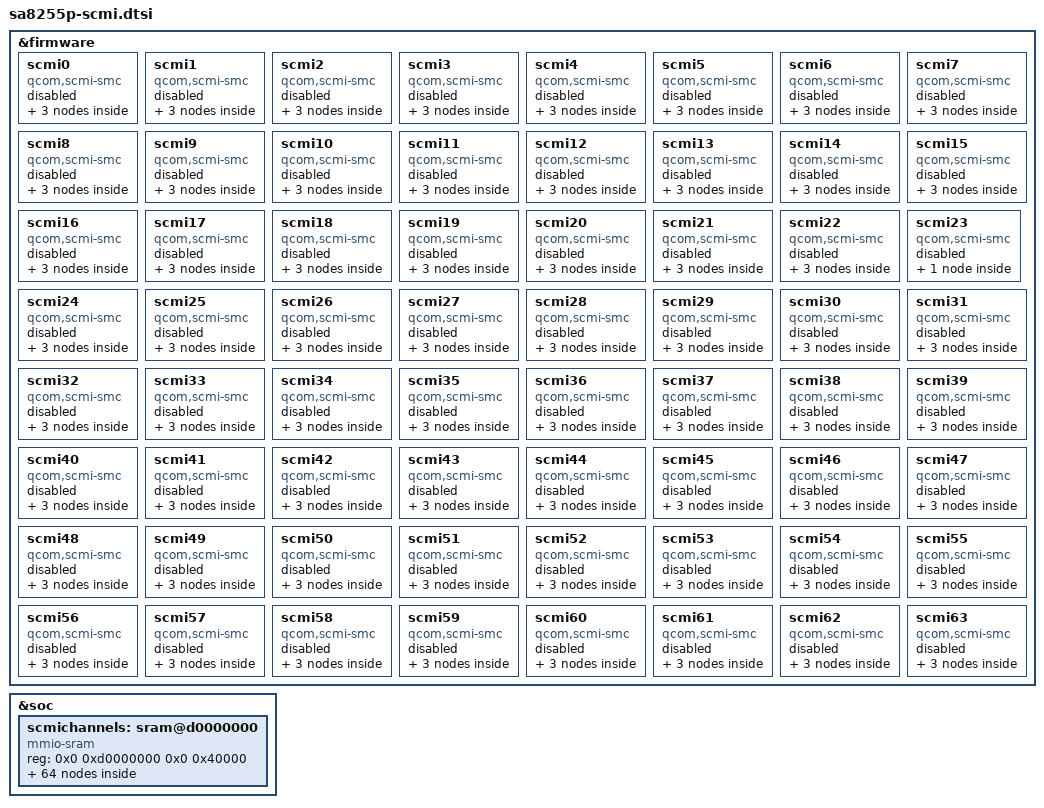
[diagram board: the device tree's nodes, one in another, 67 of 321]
// SPDX-License-Identifier: BSD-3-Clause
/*
 * Copyright (c) 2024 Qualcomm Innovation Center, Inc. All rights reserved.
 */

#include <dt-bindings/interrupt-controller/arm-gic.h>

&firmware {
	scmi0: scmi0 {
		compatible = "qcom,scmi-smc";
		arm,smc-id = <0xc6008012>;
		shmem = <&shmem0>;

		interrupts = <GIC_SPI 963 IRQ_TYPE_EDGE_RISING>;
		interrupt-names = "a2p";

		status = "disabled";

		#address-cells = <1>;
		#size-cells = <0>;

		scmi0_pd: protocol@11 {
			reg = <0x11>;
			#power-domain-cells = <1>;
		};

		scmi0_dvfs: protocol@13 {
			reg = <0x13>;
			#power-domain-cells = <1>;
		};

		scmi0_rst: protocol@16 {
			reg = <0x16>;
			#reset-cells = <1>;
		};
	};

	scmi1: scmi1 {
		compatible = "qcom,scmi-smc";
		arm,smc-id = <0xc6008012>;
		shmem = <&shmem1>;

		interrupts = <GIC_SPI 964 IRQ_TYPE_EDGE_RISING>;
		interrupt-names = "a2p";

		status = "disabled";

		#address-cells = <1>;
		#size-cells = <0>;

		scmi1_pd: protocol@11 {
			reg = <0x11>;
			#power-domain-cells = <1>;
		};

		scmi1_dvfs: protocol@13 {
			reg = <0x13>;
			#power-domain-cells = <1>;
		};

		scmi1_rst: protocol@16 {
			reg = <0x16>;
			#reset-cells = <1>;
		};
	};

	scmi2: scmi2 {
		compatible = "qcom,scmi-smc";
		arm,smc-id = <0xc6008012>;
		shmem = <&shmem2>;

		interrupts = <GIC_SPI 965 IRQ_TYPE_EDGE_RISING>;
		interrupt-names = "a2p";

		status = "disabled";

		#address-cells = <1>;
		#size-cells = <0>;

		scmi2_pd: protocol@11 {
			reg = <0x11>;
			#power-domain-cells = <1>;
		};

		scmi2_dvfs: protocol@13 {
			reg = <0x13>;
			#power-domain-cells = <1>;
		};

		scmi2_rst: protocol@16 {
			reg = <0x16>;
			#reset-cells = <1>;
		};
	};

	scmi3: scmi3 {
		compatible = "qcom,scmi-smc";
		arm,smc-id = <0xc6008012>;
		shmem = <&shmem3>;

		interrupts = <GIC_SPI 966 IRQ_TYPE_EDGE_RISING>;
		interrupt-names = "a2p";

		status = "disabled";

		#address-cells = <1>;
		#size-cells = <0>;

		scmi3_pd: protocol@11 {
			reg = <0x11>;
			#power-domain-cells = <1>;
		};

		scmi3_dvfs: protocol@13 {
			reg = <0x13>;
			#power-domain-cells = <1>;
		};

		scmi3_rst: protocol@16 {
			reg = <0x16>;
			#reset-cells = <1>;
		};
	};

	scmi4: scmi4 {
		compatible = "qcom,scmi-smc";
		arm,smc-id = <0xc6008012>;
		shmem = <&shmem4>;

		interrupts = <GIC_SPI 967 IRQ_TYPE_EDGE_RISING>;
		interrupt-names = "a2p";

		status = "disabled";

		#address-cells = <1>;
		#size-cells = <0>;

		scmi4_pd: protocol@11 {
			reg = <0x11>;
			#power-domain-cells = <1>;
		};

		scmi4_dvfs: protocol@13 {
			reg = <0x13>;
			#power-domain-cells = <1>;
		};

		scmi4_rst: protocol@16 {
			reg = <0x16>;
			#reset-cells = <1>;
		};
	};

	scmi5: scmi5 {
		compatible = "qcom,scmi-smc";
		arm,smc-id = <0xc6008012>;
		shmem = <&shmem5>;

		interrupts = <GIC_SPI 968 IRQ_TYPE_EDGE_RISING>;
		interrupt-names = "a2p";

		status = "disabled";

		#address-cells = <1>;
		#size-cells = <0>;

		scmi5_pd: protocol@11 {
			reg = <0x11>;
			#power-domain-cells = <1>;
		};

		scmi5_dvfs: protocol@13 {
			reg = <0x13>;
			#power-domain-cells = <1>;
		};

		scmi5_rst: protocol@16 {
			reg = <0x16>;
			#reset-cells = <1>;
		};
	};

	scmi6: scmi6 {
		compatible = "qcom,scmi-smc";
		arm,smc-id = <0xc6008012>;
		shmem = <&shmem6>;

		interrupts = <GIC_SPI 969 IRQ_TYPE_EDGE_RISING>;
		interrupt-names = "a2p";

		status = "disabled";

		#address-cells = <1>;
		#size-cells = <0>;

		scmi6_pd: protocol@11 {
			reg = <0x11>;
			#power-domain-cells = <1>;
		};

		scmi6_dvfs: protocol@13 {
			reg = <0x13>;
			#power-domain-cells = <1>;
		};

		scmi6_rst: protocol@16 {
			reg = <0x16>;
			#reset-cells = <1>;
		};
	};

	scmi7: scmi7 {
		compatible = "qcom,scmi-smc";
		arm,smc-id = <0xc6008012>;
		shmem = <&shmem7>;

		interrupts = <GIC_SPI 970 IRQ_TYPE_EDGE_RISING>;
		interrupt-names = "a2p";

		status = "disabled";

		#address-cells = <1>;
		#size-cells = <0>;

		scmi7_pd: protocol@11 {
			reg = <0x11>;
			#power-domain-cells = <1>;
		};

		scmi7_dvfs: protocol@13 {
			reg = <0x13>;
			#power-domain-cells = <1>;
		};

		scmi7_rst: protocol@16 {
			reg = <0x16>;
			#reset-cells = <1>;
		};
	};

	scmi8: scmi8 {
		compatible = "qcom,scmi-smc";
		arm,smc-id = <0xc6008012>;
		shmem = <&shmem8>;

		interrupts = <GIC_SPI 971 IRQ_TYPE_EDGE_RISING>;
		interrupt-names = "a2p";

		status = "disabled";

		#address-cells = <1>;
		#size-cells = <0>;

		scmi8_pd: protocol@11 {
			reg = <0x11>;
			#power-domain-cells = <1>;
		};

		scmi8_dvfs: protocol@13 {
			reg = <0x13>;
			#power-domain-cells = <1>;
		};

		scmi8_rst: protocol@16 {
			reg = <0x16>;
			#reset-cells = <1>;
		};
	};

	scmi9: scmi9 {
		compatible = "qcom,scmi-smc";
		arm,smc-id = <0xc6008012>;
		shmem = <&shmem9>;

		interrupts = <GIC_SPI 972 IRQ_TYPE_EDGE_RISING>;
		interrupt-names = "a2p";

		status = "disabled";

		#address-cells = <1>;
		#size-cells = <0>;

		scmi9_pd: protocol@11 {
			reg = <0x11>;
			#power-domain-cells = <1>;
		};

		scmi9_dvfs: protocol@13 {
			reg = <0x13>;
			#power-domain-cells = <1>;
		};

		scmi9_rst: protocol@16 {
			reg = <0x16>;
			#reset-cells = <1>;
		};
	};

	scmi10: scmi10 {
		compatible = "qcom,scmi-smc";
		arm,smc-id = <0xc6008012>;
		shmem = <&shmem10>;

		interrupts = <GIC_SPI 973 IRQ_TYPE_EDGE_RISING>;
		interrupt-names = "a2p";

		status = "disabled";

		#address-cells = <1>;
		#size-cells = <0>;

		scmi10_pd: protocol@11 {
			reg = <0x11>;
			#power-domain-cells = <1>;
		};

		scmi10_dvfs: protocol@13 {
			reg = <0x13>;
			#power-domain-cells = <1>;
		};

		scmi10_rst: protocol@16 {
			reg = <0x16>;
			#reset-cells = <1>;
		};
	};

	scmi11: scmi11 {
		compatible = "qcom,scmi-smc";
		arm,smc-id = <0xc6008012>;
		shmem = <&shmem11>;

		interrupts = <GIC_SPI 974 IRQ_TYPE_EDGE_RISING>;
		interrupt-names = "a2p";

		status = "disabled";

		#address-cells = <1>;
		#size-cells = <0>;

		scmi11_pd: protocol@11 {
			reg = <0x11>;
			#power-domain-cells = <1>;
		};

		scmi11_dvfs: protocol@13 {
			reg = <0x13>;
			#power-domain-cells = <1>;
		};

		scmi11_rst: protocol@16 {
			reg = <0x16>;
			#reset-cells = <1>;
		};
	};

	scmi12: scmi12 {
		compatible = "qcom,scmi-smc";
		arm,smc-id = <0xc6008012>;
		shmem = <&shmem12>;

		interrupts = <GIC_SPI 975 IRQ_TYPE_EDGE_RISING>;
		interrupt-names = "a2p";

		status = "disabled";

		#address-cells = <1>;
		#size-cells = <0>;

		scmi12_pd: protocol@11 {
			reg = <0x11>;
			#power-domain-cells = <1>;
		};

		scmi12_dvfs: protocol@13 {
			reg = <0x13>;
			#power-domain-cells = <1>;
		};

		scmi12_rst: protocol@16 {
			reg = <0x16>;
			#reset-cells = <1>;
		};
	};

	scmi13: scmi13 {
		compatible = "qcom,scmi-smc";
		arm,smc-id = <0xc6008012>;
		shmem = <&shmem13>;

		interrupts = <GIC_SPI 976 IRQ_TYPE_EDGE_RISING>;
		interrupt-names = "a2p";

		status = "disabled";

		#address-cells = <1>;
		#size-cells = <0>;

		scmi13_pd: protocol@11 {
			reg = <0x11>;
			#power-domain-cells = <1>;
		};

		scmi13_dvfs: protocol@13 {
			reg = <0x13>;
			#power-domain-cells = <1>;
		};

		scmi13_rst: protocol@16 {
			reg = <0x16>;
			#reset-cells = <1>;
		};
	};

	scmi14: scmi14 {
		compatible = "qcom,scmi-smc";
		arm,smc-id = <0xc6008012>;
		shmem = <&shmem14>;

		interrupts = <GIC_SPI 977 IRQ_TYPE_EDGE_RISING>;
		interrupt-names = "a2p";

		status = "disabled";

		#address-cells = <1>;
		#size-cells = <0>;

		scmi14_pd: protocol@11 {
			reg = <0x11>;
			#power-domain-cells = <1>;
		};

		scmi14_dvfs: protocol@13 {
			reg = <0x13>;
			#power-domain-cells = <1>;
		};

		scmi14_rst: protocol@16 {
			reg = <0x16>;
			#reset-cells = <1>;
		};
	};

	scmi15: scmi15 {
		compatible = "qcom,scmi-smc";
		arm,smc-id = <0xc6008012>;
		shmem = <&shmem15>;

		interrupts = <GIC_SPI 978 IRQ_TYPE_EDGE_RISING>;
		interrupt-names = "a2p";

		status = "disabled";

		#address-cells = <1>;
		#size-cells = <0>;

		scmi15_pd: protocol@11 {
			reg = <0x11>;
			#power-domain-cells = <1>;
		};

		scmi15_dvfs: protocol@13 {
			reg = <0x13>;
			#power-domain-cells = <1>;
		};

		scmi15_rst: protocol@16 {
			reg = <0x16>;
			#reset-cells = <1>;
		};
	};

	scmi16: scmi16 {
		compatible = "qcom,scmi-smc";
		arm,smc-id = <0xc6008012>;
		shmem = <&shmem16>;

		interrupts = <GIC_SPI 979 IRQ_TYPE_EDGE_RISING>;
		interrupt-names = "a2p";

		status = "disabled";

		#address-cells = <1>;
		#size-cells = <0>;

		scmi16_pd: protocol@11 {
			reg = <0x11>;
			#power-domain-cells = <1>;
		};

		scmi16_dvfs: protocol@13 {
			reg = <0x13>;
			#power-domain-cells = <1>;
		};

		scmi16_rst: protocol@16 {
			reg = <0x16>;
			#reset-cells = <1>;
		};
	};

	scmi17: scmi17 {
		compatible = "qcom,scmi-smc";
		arm,smc-id = <0xc6008012>;
		shmem = <&shmem17>;

		interrupts = <GIC_SPI 980 IRQ_TYPE_EDGE_RISING>;
		interrupt-names = "a2p";

		status = "disabled";

		#address-cells = <1>;
		#size-cells = <0>;

		scmi17_pd: protocol@11 {
			reg = <0x11>;
			#power-domain-cells = <1>;
		};

		scmi17_dvfs: protocol@13 {
			reg = <0x13>;
			#power-domain-cells = <1>;
		};

		scmi17_rst: protocol@16 {
			reg = <0x16>;
			#reset-cells = <1>;
		};
	};

	scmi18: scmi18 {
		compatible = "qcom,scmi-smc";
		arm,smc-id = <0xc6008012>;
		shmem = <&shmem18>;

		interrupts = <GIC_SPI 981 IRQ_TYPE_EDGE_RISING>;
		interrupt-names = "a2p";

		status = "disabled";

		#address-cells = <1>;
		#size-cells = <0>;

		scmi18_pd: protocol@11 {
			reg = <0x11>;
			#power-domain-cells = <1>;
		};

		scmi18_dvfs: protocol@13 {
			reg = <0x13>;
			#power-domain-cells = <1>;
		};

		scmi18_rst: protocol@16 {
			reg = <0x16>;
			#reset-cells = <1>;
		};
	};

	scmi19: scmi19 {
		compatible = "qcom,scmi-smc";
		arm,smc-id = <0xc6008012>;
		shmem = <&shmem19>;

		interrupts = <GIC_SPI 982 IRQ_TYPE_EDGE_RISING>;
		interrupt-names = "a2p";

		status = "disabled";

		#address-cells = <1>;
		#size-cells = <0>;

		scmi19_pd: protocol@11 {
			reg = <0x11>;
			#power-domain-cells = <1>;
		};

		scmi19_dvfs: protocol@13 {
			reg = <0x13>;
			#power-domain-cells = <1>;
		};

		scmi19_rst: protocol@16 {
			reg = <0x16>;
			#reset-cells = <1>;
		};
	};

	scmi20: scmi20 {
		compatible = "qcom,scmi-smc";
		arm,smc-id = <0xc6008012>;
		shmem = <&shmem20>;

		interrupts = <GIC_SPI 983 IRQ_TYPE_EDGE_RISING>;
		interrupt-names = "a2p";

		status = "disabled";

		#address-cells = <1>;
		#size-cells = <0>;

		scmi20_pd: protocol@11 {
			reg = <0x11>;
			#power-domain-cells = <1>;
		};

		scmi20_dvfs: protocol@13 {
			reg = <0x13>;
			#power-domain-cells = <1>;
		};

		scmi20_rst: protocol@16 {
			reg = <0x16>;
			#reset-cells = <1>;
		};
	};

	scmi21: scmi21 {
		compatible = "qcom,scmi-smc";
		arm,smc-id = <0xc6008012>;
		shmem = <&shmem21>;

		interrupts = <GIC_SPI 984 IRQ_TYPE_EDGE_RISING>;
		interrupt-names = "a2p";

		status = "disabled";

		#address-cells = <1>;
		#size-cells = <0>;

		scmi21_pd: protocol@11 {
			reg = <0x11>;
			#power-domain-cells = <1>;
		};

		scmi21_dvfs: protocol@13 {
			reg = <0x13>;
			#power-domain-cells = <1>;
		};

		scmi21_rst: protocol@16 {
			reg = <0x16>;
			#reset-cells = <1>;
		};
	};

	scmi22: scmi22 {
		compatible = "qcom,scmi-smc";
		arm,smc-id = <0xc6008012>;
		shmem = <&shmem22>;

		interrupts = <GIC_SPI 985 IRQ_TYPE_EDGE_RISING>;
		interrupt-names = "a2p";

		status = "disabled";

		#address-cells = <1>;
		#size-cells = <0>;

		scmi22_pd: protocol@11 {
			reg = <0x11>;
			#power-domain-cells = <1>;
		};

		scmi22_dvfs: protocol@13 {
			reg = <0x13>;
			#power-domain-cells = <1>;
		};

		scmi22_rst: protocol@16 {
			reg = <0x16>;
			#reset-cells = <1>;
		};
	};

	scmi23: scmi23 {
		compatible = "qcom,scmi-smc";
		arm,smc-id = <0xc6008012>;
		shmem = <&shmem23>;

		interrupts = <GIC_SPI 986 IRQ_TYPE_EDGE_RISING>;
		interrupt-names = "a2p";

		status = "disabled";

		#address-cells = <1>;
		#size-cells = <0>;

		scmi23_sensor: protocol@15 {
			reg = <0x15>;
			#thermal-sensor-cells = <1>;
		};
	};

	scmi24: scmi24 {
		compatible = "qcom,scmi-smc";
		arm,smc-id = <0xc6008012>;
		shmem = <&shmem24>;

		interrupts = <GIC_SPI 987 IRQ_TYPE_EDGE_RISING>;
		interrupt-names = "a2p";

		status = "disabled";

		#address-cells = <1>;
		#size-cells = <0>;

		scmi24_pd: protocol@11 {
			reg = <0x11>;
			#power-domain-cells = <1>;
		};

		scmi24_dvfs: protocol@13 {
			reg = <0x13>;
			#power-domain-cells = <1>;
		};

		scmi24_rst: protocol@16 {
			reg = <0x16>;
			#reset-cells = <1>;
		};
	};

	scmi25: scmi25 {
		compatible = "qcom,scmi-smc";
		arm,smc-id = <0xc6008012>;
		shmem = <&shmem25>;

		interrupts = <GIC_ESPI 0 IRQ_TYPE_EDGE_RISING>;
		interrupt-names = "a2p";

		status = "disabled";

		#address-cells = <1>;
		#size-cells = <0>;

		scmi25_pd: protocol@11 {
			reg = <0x11>;
			#power-domain-cells = <1>;
		};

		scmi25_dvfs: protocol@13 {
			reg = <0x13>;
			#power-domain-cells = <1>;
		};

		scmi25_rst: protocol@16 {
			reg = <0x16>;
			#reset-cells = <1>;
		};
	};

	scmi26: scmi26 {
		compatible = "qcom,scmi-smc";
		arm,smc-id = <0xc6008012>;
		shmem = <&shmem26>;

		interrupts = <GIC_ESPI 1 IRQ_TYPE_EDGE_RISING>;
		interrupt-names = "a2p";

		status = "disabled";

		#address-cells = <1>;
		#size-cells = <0>;

		scmi26_pd: protocol@11 {
			reg = <0x11>;
			#power-domain-cells = <1>;
		};

		scmi26_dvfs: protocol@13 {
			reg = <0x13>;
			#power-domain-cells = <1>;
		};

		scmi26_rst: protocol@16 {
			reg = <0x16>;
			#reset-cells = <1>;
		};
	};

	scmi27: scmi27 {
		compatible = "qcom,scmi-smc";
		arm,smc-id = <0xc6008012>;
		shmem = <&shmem27>;

		interrupts = <GIC_ESPI 2 IRQ_TYPE_EDGE_RISING>;
		interrupt-names = "a2p";

		status = "disabled";

		#address-cells = <1>;
		#size-cells = <0>;

		scmi27_pd: protocol@11 {
			reg = <0x11>;
			#power-domain-cells = <1>;
		};

		scmi27_dvfs: protocol@13 {
			reg = <0x13>;
			#power-domain-cells = <1>;
		};

		scmi27_rst: protocol@16 {
			reg = <0x16>;
			#reset-cells = <1>;
		};
	};

	scmi28: scmi28 {
		compatible = "qcom,scmi-smc";
		arm,smc-id = <0xc6008012>;
		shmem = <&shmem28>;

		interrupts = <GIC_ESPI 3 IRQ_TYPE_EDGE_RISING>;
		interrupt-names = "a2p";

		status = "disabled";

		#address-cells = <1>;
		#size-cells = <0>;

		scmi28_pd: protocol@11 {
			reg = <0x11>;
			#power-domain-cells = <1>;
		};

		scmi28_dvfs: protocol@13 {
			reg = <0x13>;
			#power-domain-cells = <1>;
		};

		scmi28_rst: protocol@16 {
			reg = <0x16>;
			#reset-cells = <1>;
		};
	};

	scmi29: scmi29 {
		compatible = "qcom,scmi-smc";
		arm,smc-id = <0xc6008012>;
		shmem = <&shmem29>;

		interrupts = <GIC_ESPI 4 IRQ_TYPE_EDGE_RISING>;
		interrupt-names = "a2p";

		status = "disabled";

		#address-cells = <1>;
		#size-cells = <0>;

		scmi29_pd: protocol@11 {
			reg = <0x11>;
			#power-domain-cells = <1>;
		};

		scmi29_dvfs: protocol@13 {
			reg = <0x13>;
			#power-domain-cells = <1>;
		};

		scmi29_rst: protocol@16 {
			reg = <0x16>;
			#reset-cells = <1>;
		};
	};

	scmi30: scmi30 {
		compatible = "qcom,scmi-smc";
		arm,smc-id = <0xc6008012>;
		shmem = <&shmem30>;

		interrupts = <GIC_ESPI 5 IRQ_TYPE_EDGE_RISING>;
		interrupt-names = "a2p";

		status = "disabled";

		#address-cells = <1>;
		#size-cells = <0>;

		scmi30_pd: protocol@11 {
			reg = <0x11>;
			#power-domain-cells = <1>;
		};

		scmi30_dvfs: protocol@13 {
			reg = <0x13>;
			#power-domain-cells = <1>;
		};

		scmi30_rst: protocol@16 {
			reg = <0x16>;
			#reset-cells = <1>;
		};
	};

	scmi31: scmi31 {
		compatible = "qcom,scmi-smc";
		arm,smc-id = <0xc6008012>;
		shmem = <&shmem31>;

		interrupts = <GIC_ESPI 6 IRQ_TYPE_EDGE_RISING>;
		interrupt-names = "a2p";

		status = "disabled";

		#address-cells = <1>;
		#size-cells = <0>;

		scmi31_pd: protocol@11 {
			reg = <0x11>;
			#power-domain-cells = <1>;
		};

		scmi31_dvfs: protocol@13 {
			reg = <0x13>;
			#power-domain-cells = <1>;
		};

		scmi31_rst: protocol@16 {
			reg = <0x16>;
			#reset-cells = <1>;
		};
	};

	scmi32: scmi32 {
		compatible = "qcom,scmi-smc";
		arm,smc-id = <0xc6008012>;
		shmem = <&shmem32>;

		interrupts = <GIC_ESPI 7 IRQ_TYPE_EDGE_RISING>;
		interrupt-names = "a2p";

		status = "disabled";

		#address-cells = <1>;
		#size-cells = <0>;

		scmi32_pd: protocol@11 {
			reg = <0x11>;
			#power-domain-cells = <1>;
		};

		scmi32_dvfs: protocol@13 {
			reg = <0x13>;
			#power-domain-cells = <1>;
		};

		scmi32_rst: protocol@16 {
			reg = <0x16>;
			#reset-cells = <1>;
		};
	};

	scmi33: scmi33 {
		compatible = "qcom,scmi-smc";
		arm,smc-id = <0xc6008012>;
		shmem = <&shmem33>;

		interrupts = <GIC_ESPI 8 IRQ_TYPE_EDGE_RISING>;
		interrupt-names = "a2p";

		status = "disabled";

		#address-cells = <1>;
		#size-cells = <0>;

		scmi33_pd: protocol@11 {
			reg = <0x11>;
			#power-domain-cells = <1>;
		};

		scmi33_dvfs: protocol@13 {
			reg = <0x13>;
			#power-domain-cells = <1>;
		};

		scmi33_rst: protocol@16 {
			reg = <0x16>;
			#reset-cells = <1>;
		};
	};

	scmi34: scmi34 {
		compatible = "qcom,scmi-smc";
		arm,smc-id = <0xc6008012>;
		shmem = <&shmem34>;

		interrupts = <GIC_ESPI 9 IRQ_TYPE_EDGE_RISING>;
		interrupt-names = "a2p";

		status = "disabled";

		#address-cells = <1>;
		#size-cells = <0>;

		scmi34_pd: protocol@11 {
			reg = <0x11>;
			#power-domain-cells = <1>;
		};

		scmi34_dvfs: protocol@13 {
			reg = <0x13>;
			#power-domain-cells = <1>;
		};

		scmi34_rst: protocol@16 {
			reg = <0x16>;
			#reset-cells = <1>;
		};
	};

	scmi35: scmi35 {
		compatible = "qcom,scmi-smc";
		arm,smc-id = <0xc6008012>;
		shmem = <&shmem35>;

		interrupts = <GIC_ESPI 10 IRQ_TYPE_EDGE_RISING>;
		interrupt-names = "a2p";

		status = "disabled";

		#address-cells = <1>;
		#size-cells = <0>;

		scmi35_pd: protocol@11 {
			reg = <0x11>;
			#power-domain-cells = <1>;
		};

		scmi35_dvfs: protocol@13 {
			reg = <0x13>;
			#power-domain-cells = <1>;
		};

		scmi35_rst: protocol@16 {
			reg = <0x16>;
			#reset-cells = <1>;
		};
	};

	scmi36: scmi36 {
		compatible = "qcom,scmi-smc";
		arm,smc-id = <0xc6008012>;
		shmem = <&shmem36>;

		interrupts = <GIC_ESPI 11 IRQ_TYPE_EDGE_RISING>;
		interrupt-names = "a2p";

		status = "disabled";

		#address-cells = <1>;
		#size-cells = <0>;

		scmi36_pd: protocol@11 {
			reg = <0x11>;
			#power-domain-cells = <1>;
		};

		scmi36_dvfs: protocol@13 {
			reg = <0x13>;
			#power-domain-cells = <1>;
		};

		scmi36_rst: protocol@16 {
			reg = <0x16>;
			#reset-cells = <1>;
		};
	};

	scmi37: scmi37 {
		compatible = "qcom,scmi-smc";
		arm,smc-id = <0xc6008012>;
		shmem = <&shmem37>;

		interrupts = <GIC_ESPI 12 IRQ_TYPE_EDGE_RISING>;
		interrupt-names = "a2p";

		status = "disabled";

		#address-cells = <1>;
		#size-cells = <0>;

		scmi37_pd: protocol@11 {
			reg = <0x11>;
			#power-domain-cells = <1>;
		};

		scmi37_dvfs: protocol@13 {
			reg = <0x13>;
			#power-domain-cells = <1>;
		};

		scmi37_rst: protocol@16 {
			reg = <0x16>;
			#reset-cells = <1>;
		};
	};

	scmi38: scmi38 {
		compatible = "qcom,scmi-smc";
		arm,smc-id = <0xc6008012>;
		shmem = <&shmem38>;

		interrupts = <GIC_ESPI 13 IRQ_TYPE_EDGE_RISING>;
		interrupt-names = "a2p";

		status = "disabled";

		#address-cells = <1>;
		#size-cells = <0>;

		scmi38_pd: protocol@11 {
			reg = <0x11>;
			#power-domain-cells = <1>;
		};

		scmi38_dvfs: protocol@13 {
			reg = <0x13>;
			#power-domain-cells = <1>;
		};

		scmi38_rst: protocol@16 {
			reg = <0x16>;
			#reset-cells = <1>;
		};
	};

	scmi39: scmi39 {
		compatible = "qcom,scmi-smc";
		arm,smc-id = <0xc6008012>;
		shmem = <&shmem39>;

		interrupts = <GIC_ESPI 14 IRQ_TYPE_EDGE_RISING>;
		interrupt-names = "a2p";

		status = "disabled";

		#address-cells = <1>;
		#size-cells = <0>;

		scmi39_pd: protocol@11 {
			reg = <0x11>;
			#power-domain-cells = <1>;
		};

		scmi39_dvfs: protocol@13 {
			reg = <0x13>;
			#power-domain-cells = <1>;
		};

		scmi39_rst: protocol@16 {
			reg = <0x16>;
			#reset-cells = <1>;
		};
	};

	scmi40: scmi40 {
		compatible = "qcom,scmi-smc";
		arm,smc-id = <0xc6008012>;
		shmem = <&shmem40>;

		interrupts = <GIC_ESPI 15 IRQ_TYPE_EDGE_RISING>;
		interrupt-names = "a2p";

		status = "disabled";

		#address-cells = <1>;
		#size-cells = <0>;

		scmi40_pd: protocol@11 {
			reg = <0x11>;
			#power-domain-cells = <1>;
		};

		scmi40_dvfs: protocol@13 {
			reg = <0x13>;
			#power-domain-cells = <1>;
		};

		scmi40_rst: protocol@16 {
			reg = <0x16>;
			#reset-cells = <1>;
		};
	};

	scmi41: scmi41 {
		compatible = "qcom,scmi-smc";
		arm,smc-id = <0xc6008012>;
		shmem = <&shmem41>;

		interrupts = <GIC_ESPI 16 IRQ_TYPE_EDGE_RISING>;
		interrupt-names = "a2p";

		status = "disabled";

		#address-cells = <1>;
		#size-cells = <0>;

		scmi41_pd: protocol@11 {
			reg = <0x11>;
			#power-domain-cells = <1>;
		};

		scmi41_dvfs: protocol@13 {
			reg = <0x13>;
			#power-domain-cells = <1>;
		};

		scmi41_rst: protocol@16 {
			reg = <0x16>;
			#reset-cells = <1>;
		};
	};

	scmi42: scmi42 {
		compatible = "qcom,scmi-smc";
		arm,smc-id = <0xc6008012>;
		shmem = <&shmem42>;

		interrupts = <GIC_ESPI 17 IRQ_TYPE_EDGE_RISING>;
		interrupt-names = "a2p";

		status = "disabled";

		#address-cells = <1>;
		#size-cells = <0>;

		scmi42_pd: protocol@11 {
			reg = <0x11>;
			#power-domain-cells = <1>;
		};

		scmi42_dvfs: protocol@13 {
			reg = <0x13>;
			#power-domain-cells = <1>;
		};

		scmi42_rst: protocol@16 {
			reg = <0x16>;
			#reset-cells = <1>;
		};
	};

	scmi43: scmi43 {
		compatible = "qcom,scmi-smc";
		arm,smc-id = <0xc6008012>;
		shmem = <&shmem43>;

		interrupts = <GIC_ESPI 18 IRQ_TYPE_EDGE_RISING>;
		interrupt-names = "a2p";

		status = "disabled";

		#address-cells = <1>;
		#size-cells = <0>;

		scmi43_pd: protocol@11 {
			reg = <0x11>;
			#power-domain-cells = <1>;
		};

		scmi43_dvfs: protocol@13 {
			reg = <0x13>;
			#power-domain-cells = <1>;
		};

		scmi43_rst: protocol@16 {
			reg = <0x16>;
			#reset-cells = <1>;
		};
	};

	scmi44: scmi44 {
		compatible = "qcom,scmi-smc";
		arm,smc-id = <0xc6008012>;
		shmem = <&shmem44>;

		interrupts = <GIC_ESPI 19 IRQ_TYPE_EDGE_RISING>;
		interrupt-names = "a2p";

		status = "disabled";

		#address-cells = <1>;
		#size-cells = <0>;

		scmi44_pd: protocol@11 {
			reg = <0x11>;
			#power-domain-cells = <1>;
		};

		scmi44_dvfs: protocol@13 {
			reg = <0x13>;
			#power-domain-cells = <1>;
		};

		scmi44_rst: protocol@16 {
			reg = <0x16>;
			#reset-cells = <1>;
		};
	};

	scmi45: scmi45 {
		compatible = "qcom,scmi-smc";
		arm,smc-id = <0xc6008012>;
		shmem = <&shmem45>;

		interrupts = <GIC_ESPI 20 IRQ_TYPE_EDGE_RISING>;
		interrupt-names = "a2p";

		status = "disabled";

		#address-cells = <1>;
		#size-cells = <0>;

		scmi45_pd: protocol@11 {
			reg = <0x11>;
			#power-domain-cells = <1>;
		};

		scmi45_dvfs: protocol@13 {
			reg = <0x13>;
			#power-domain-cells = <1>;
		};

		scmi45_rst: protocol@16 {
			reg = <0x16>;
			#reset-cells = <1>;
		};
	};

	scmi46: scmi46 {
		compatible = "qcom,scmi-smc";
		arm,smc-id = <0xc6008012>;
		shmem = <&shmem46>;

		interrupts = <GIC_ESPI 21 IRQ_TYPE_EDGE_RISING>;
		interrupt-names = "a2p";

		status = "disabled";

		#address-cells = <1>;
		#size-cells = <0>;

		scmi46_pd: protocol@11 {
			reg = <0x11>;
			#power-domain-cells = <1>;
		};

		scmi46_dvfs: protocol@13 {
			reg = <0x13>;
			#power-domain-cells = <1>;
		};

		scmi46_rst: protocol@16 {
			reg = <0x16>;
			#reset-cells = <1>;
		};
	};

	scmi47: scmi47 {
		compatible = "qcom,scmi-smc";
		arm,smc-id = <0xc6008012>;
		shmem = <&shmem47>;

		interrupts = <GIC_ESPI 22 IRQ_TYPE_EDGE_RISING>;
		interrupt-names = "a2p";

		status = "disabled";

		#address-cells = <1>;
		#size-cells = <0>;

		scmi47_pd: protocol@11 {
			reg = <0x11>;
			#power-domain-cells = <1>;
		};

		scmi47_dvfs: protocol@13 {
			reg = <0x13>;
			#power-domain-cells = <1>;
		};

		scmi47_rst: protocol@16 {
			reg = <0x16>;
			#reset-cells = <1>;
		};
	};

	scmi48: scmi48 {
		compatible = "qcom,scmi-smc";
		arm,smc-id = <0xc6008012>;
		shmem = <&shmem48>;

		interrupts = <GIC_ESPI 23 IRQ_TYPE_EDGE_RISING>;
		interrupt-names = "a2p";

		status = "disabled";

		#address-cells = <1>;
		#size-cells = <0>;

		scmi48_pd: protocol@11 {
			reg = <0x11>;
			#power-domain-cells = <1>;
		};

		scmi48_dvfs: protocol@13 {
			reg = <0x13>;
			#power-domain-cells = <1>;
		};

		scmi48_rst: protocol@16 {
			reg = <0x16>;
			#reset-cells = <1>;
		};
	};

	scmi49: scmi49 {
		compatible = "qcom,scmi-smc";
		arm,smc-id = <0xc6008012>;
		shmem = <&shmem49>;

		interrupts = <GIC_ESPI 24 IRQ_TYPE_EDGE_RISING>;
		interrupt-names = "a2p";

		status = "disabled";

		#address-cells = <1>;
		#size-cells = <0>;

		scmi49_pd: protocol@11 {
			reg = <0x11>;
			#power-domain-cells = <1>;
		};

		scmi49_dvfs: protocol@13 {
			reg = <0x13>;
			#power-domain-cells = <1>;
		};

		scmi49_rst: protocol@16 {
			reg = <0x16>;
			#reset-cells = <1>;
		};
	};

	scmi50: scmi50 {
		compatible = "qcom,scmi-smc";
		arm,smc-id = <0xc6008012>;
		shmem = <&shmem50>;

		interrupts = <GIC_ESPI 25 IRQ_TYPE_EDGE_RISING>;
		interrupt-names = "a2p";

		status = "disabled";

		#address-cells = <1>;
		#size-cells = <0>;

		scmi50_pd: protocol@11 {
			reg = <0x11>;
			#power-domain-cells = <1>;
		};

		scmi50_dvfs: protocol@13 {
			reg = <0x13>;
			#power-domain-cells = <1>;
		};

		scmi50_rst: protocol@16 {
			reg = <0x16>;
			#reset-cells = <1>;
		};
	};

	scmi51: scmi51 {
		compatible = "qcom,scmi-smc";
		arm,smc-id = <0xc6008012>;
		shmem = <&shmem51>;

		interrupts = <GIC_ESPI 26 IRQ_TYPE_EDGE_RISING>;
		interrupt-names = "a2p";

		status = "disabled";

		#address-cells = <1>;
		#size-cells = <0>;

		scmi51_pd: protocol@11 {
			reg = <0x11>;
			#power-domain-cells = <1>;
		};

		scmi51_dvfs: protocol@13 {
			reg = <0x13>;
			#power-domain-cells = <1>;
		};

		scmi51_rst: protocol@16 {
			reg = <0x16>;
			#reset-cells = <1>;
		};
	};

	scmi52: scmi52 {
		compatible = "qcom,scmi-smc";
		arm,smc-id = <0xc6008012>;
		shmem = <&shmem52>;

		interrupts = <GIC_ESPI 27 IRQ_TYPE_EDGE_RISING>;
		interrupt-names = "a2p";

		status = "disabled";

		#address-cells = <1>;
		#size-cells = <0>;

		scmi52_pd: protocol@11 {
			reg = <0x11>;
			#power-domain-cells = <1>;
		};

		scmi52_dvfs: protocol@13 {
			reg = <0x13>;
			#power-domain-cells = <1>;
		};

		scmi52_rst: protocol@16 {
			reg = <0x16>;
			#reset-cells = <1>;
		};
	};

	scmi53: scmi53 {
		compatible = "qcom,scmi-smc";
		arm,smc-id = <0xc6008012>;
		shmem = <&shmem53>;

		interrupts = <GIC_ESPI 28 IRQ_TYPE_EDGE_RISING>;
		interrupt-names = "a2p";

		status = "disabled";

		#address-cells = <1>;
		#size-cells = <0>;

		scmi53_pd: protocol@11 {
			reg = <0x11>;
			#power-domain-cells = <1>;
		};

		scmi53_dvfs: protocol@13 {
			reg = <0x13>;
			#power-domain-cells = <1>;
		};

		scmi53_rst: protocol@16 {
			reg = <0x16>;
			#reset-cells = <1>;
		};
	};

	scmi54: scmi54 {
		compatible = "qcom,scmi-smc";
		arm,smc-id = <0xc6008012>;
		shmem = <&shmem54>;

		interrupts = <GIC_ESPI 29 IRQ_TYPE_EDGE_RISING>;
		interrupt-names = "a2p";

		status = "disabled";

		#address-cells = <1>;
		#size-cells = <0>;

		scmi54_pd: protocol@11 {
			reg = <0x11>;
			#power-domain-cells = <1>;
		};

		scmi54_dvfs: protocol@13 {
			reg = <0x13>;
			#power-domain-cells = <1>;
		};

		scmi54_rst: protocol@16 {
			reg = <0x16>;
			#reset-cells = <1>;
		};
	};

	scmi55: scmi55 {
		compatible = "qcom,scmi-smc";
		arm,smc-id = <0xc6008012>;
		shmem = <&shmem55>;

		interrupts = <GIC_ESPI 30 IRQ_TYPE_EDGE_RISING>;
		interrupt-names = "a2p";

		status = "disabled";

		#address-cells = <1>;
		#size-cells = <0>;

		scmi55_pd: protocol@11 {
			reg = <0x11>;
			#power-domain-cells = <1>;
		};

		scmi55_dvfs: protocol@13 {
			reg = <0x13>;
			#power-domain-cells = <1>;
		};

		scmi55_rst: protocol@16 {
			reg = <0x16>;
			#reset-cells = <1>;
		};
	};

	scmi56: scmi56 {
		compatible = "qcom,scmi-smc";
		arm,smc-id = <0xc6008012>;
		shmem = <&shmem56>;

		interrupts = <GIC_ESPI 31 IRQ_TYPE_EDGE_RISING>;
		interrupt-names = "a2p";

		status = "disabled";

		#address-cells = <1>;
		#size-cells = <0>;

		scmi56_pd: protocol@11 {
			reg = <0x11>;
			#power-domain-cells = <1>;
		};

		scmi56_dvfs: protocol@13 {
			reg = <0x13>;
			#power-domain-cells = <1>;
		};

		scmi56_rst: protocol@16 {
			reg = <0x16>;
			#reset-cells = <1>;
		};
	};

	scmi57: scmi57 {
		compatible = "qcom,scmi-smc";
		arm,smc-id = <0xc6008012>;
		shmem = <&shmem57>;

		interrupts = <GIC_ESPI 32 IRQ_TYPE_EDGE_RISING>;
		interrupt-names = "a2p";

		status = "disabled";

		#address-cells = <1>;
		#size-cells = <0>;

		scmi57_pd: protocol@11 {
			reg = <0x11>;
			#power-domain-cells = <1>;
		};

		scmi57_dvfs: protocol@13 {
			reg = <0x13>;
			#power-domain-cells = <1>;
		};

		scmi57_rst: protocol@16 {
			reg = <0x16>;
			#reset-cells = <1>;
		};
	};

	scmi58: scmi58 {
		compatible = "qcom,scmi-smc";
		arm,smc-id = <0xc6008012>;
		shmem = <&shmem58>;

		interrupts = <GIC_ESPI 33 IRQ_TYPE_EDGE_RISING>;
		interrupt-names = "a2p";

		status = "disabled";

		#address-cells = <1>;
		#size-cells = <0>;

		scmi58_pd: protocol@11 {
			reg = <0x11>;
			#power-domain-cells = <1>;
		};

		scmi58_dvfs: protocol@13 {
			reg = <0x13>;
			#power-domain-cells = <1>;
		};

		scmi58_rst: protocol@16 {
			reg = <0x16>;
			#reset-cells = <1>;
		};
	};

	scmi59: scmi59 {
		compatible = "qcom,scmi-smc";
		arm,smc-id = <0xc6008012>;
		shmem = <&shmem59>;

		interrupts = <GIC_ESPI 34 IRQ_TYPE_EDGE_RISING>;
		interrupt-names = "a2p";

		status = "disabled";

		#address-cells = <1>;
		#size-cells = <0>;

		scmi59_pd: protocol@11 {
			reg = <0x11>;
			#power-domain-cells = <1>;
		};

		scmi59_dvfs: protocol@13 {
			reg = <0x13>;
			#power-domain-cells = <1>;
		};

		scmi59_rst: protocol@16 {
			reg = <0x16>;
			#reset-cells = <1>;
		};
	};

	scmi60: scmi60 {
		compatible = "qcom,scmi-smc";
		arm,smc-id = <0xc6008012>;
		shmem = <&shmem60>;

		interrupts = <GIC_ESPI 35 IRQ_TYPE_EDGE_RISING>;
		interrupt-names = "a2p";

		status = "disabled";

		#address-cells = <1>;
		#size-cells = <0>;

		scmi60_pd: protocol@11 {
			reg = <0x11>;
			#power-domain-cells = <1>;
		};

		scmi60_dvfs: protocol@13 {
			reg = <0x13>;
			#power-domain-cells = <1>;
		};

		scmi60_rst: protocol@16 {
			reg = <0x16>;
			#reset-cells = <1>;
		};
	};

	scmi61: scmi61 {
		compatible = "qcom,scmi-smc";
		arm,smc-id = <0xc6008012>;
		shmem = <&shmem61>;

		interrupts = <GIC_ESPI 36 IRQ_TYPE_EDGE_RISING>;
		interrupt-names = "a2p";

		status = "disabled";

		#address-cells = <1>;
		#size-cells = <0>;

		scmi61_pd: protocol@11 {
			reg = <0x11>;
			#power-domain-cells = <1>;
		};

		scmi61_dvfs: protocol@13 {
			reg = <0x13>;
			#power-domain-cells = <1>;
		};

		scmi61_rst: protocol@16 {
			reg = <0x16>;
			#reset-cells = <1>;
		};
	};

	scmi62: scmi62 {
		compatible = "qcom,scmi-smc";
		arm,smc-id = <0xc6008012>;
		shmem = <&shmem62>;

		interrupts = <GIC_ESPI 37 IRQ_TYPE_EDGE_RISING>;
		interrupt-names = "a2p";

		status = "disabled";

		#address-cells = <1>;
		#size-cells = <0>;

		scmi62_pd: protocol@11 {
			reg = <0x11>;
			#power-domain-cells = <1>;
		};

		scmi62_dvfs: protocol@13 {
			reg = <0x13>;
			#power-domain-cells = <1>;
		};

		scmi62_rst: protocol@16 {
			reg = <0x16>;
			#reset-cells = <1>;
		};
	};

	scmi63: scmi63 {
		compatible = "qcom,scmi-smc";
		arm,smc-id = <0xc6008012>;
		shmem = <&shmem63>;

		interrupts = <GIC_ESPI 38 IRQ_TYPE_EDGE_RISING>;
		interrupt-names = "a2p";

		status = "disabled";

		#address-cells = <1>;
		#size-cells = <0>;

		scmi63_pd: protocol@11 {
			reg = <0x11>;
			#power-domain-cells = <1>;
		};

		scmi63_dvfs: protocol@13 {
			reg = <0x13>;
			#power-domain-cells = <1>;
		};

		scmi63_rst: protocol@16 {
			reg = <0x16>;
			#reset-cells = <1>;
		};
	};
};

&soc {
	scmichannels: sram@d0000000 {
		#address-cells = <1>;
		#size-cells = <1>;
		compatible = "mmio-sram";
		reg = <0x0 0xd0000000 0x0 0x40000>;
		ranges = <0x0 0x0 0x0 0xffffffff>;

		shmem0: scmi-sram@d0000000 {
			compatible = "arm,scmi-shmem";
			reg = <0xd0000000 0x1000>;
		};

		shmem1: scmi-sram@d0001000 {
			compatible = "arm,scmi-shmem";
			reg = <0xd0001000 0x1000>;
		};

		shmem2: scmi-sram@d0002000 {
			compatible = "arm,scmi-shmem";
			reg = <0xd0002000 0x1000>;
		};

		shmem3: scmi-sram@d0003000 {
			compatible = "arm,scmi-shmem";
			reg = <0xd0003000 0x1000>;
		};

		shmem4: scmi-sram@d0004000 {
			compatible = "arm,scmi-shmem";
			reg = <0xd0004000 0x1000>;
		};

		shmem5: scmi-sram@d0005000 {
			compatible = "arm,scmi-shmem";
			reg = <0xd0005000 0x1000>;
		};

		shmem6: scmi-sram@d0006000 {
			compatible = "arm,scmi-shmem";
			reg = <0xd0006000 0x1000>;
		};

		shmem7: scmi-sram@d0007000 {
			compatible = "arm,scmi-shmem";
			reg = <0xd0007000 0x1000>;
		};

		shmem8: scmi-sram@d0008000 {
			compatible = "arm,scmi-shmem";
			reg = <0xd0008000 0x1000>;
		};

		shmem9: scmi-sram@d0009000 {
			compatible = "arm,scmi-shmem";
			reg = <0xd0009000 0x1000>;
		};

		shmem10: scmi-sram@d000a000 {
			compatible = "arm,scmi-shmem";
			reg = <0xd000a000 0x1000>;
		};

		shmem11: scmi-sram@d000b000 {
			compatible = "arm,scmi-shmem";
			reg = <0xd000b000 0x1000>;
		};

		shmem12: scmi-sram@d000c000 {
			compatible = "arm,scmi-shmem";
			reg = <0xd000c000 0x1000>;
		};

		shmem13: scmi-sram@d000d000 {
			compatible = "arm,scmi-shmem";
			reg = <0xd000d000 0x1000>;
		};

		shmem14: scmi-sram@d000e000 {
			compatible = "arm,scmi-shmem";
			reg = <0xd000e000 0x1000>;
		};

		shmem15: scmi-sram@d000f000 {
			compatible = "arm,scmi-shmem";
			reg = <0xd000f000 0x1000>;
		};

		shmem16: scmi-sram@d0010000 {
			compatible = "arm,scmi-shmem";
			reg = <0xd0010000 0x1000>;
		};

		shmem17: scmi-sram@d0011000 {
			compatible = "arm,scmi-shmem";
			reg = <0xd0011000 0x1000>;
		};

		shmem18: scmi-sram@d0012000 {
			compatible = "arm,scmi-shmem";
			reg = <0xd0012000 0x1000>;
		};

		shmem19: scmi-sram@d0013000 {
			compatible = "arm,scmi-shmem";
			reg = <0xd0013000 0x1000>;
		};

		shmem20: scmi-sram@d0014000 {
			compatible = "arm,scmi-shmem";
			reg = <0xd0014000 0x1000>;
		};

		shmem21: scmi-sram@d0015000 {
			compatible = "arm,scmi-shmem";
			reg = <0xd0015000 0x1000>;
		};

		shmem22: scmi-sram@d0016000 {
			compatible = "arm,scmi-shmem";
			reg = <0xd0016000 0x1000>;
		};

		shmem23: scmi-sram@d0017000 {
			compatible = "arm,scmi-shmem";
			reg = <0xd0017000 0x1000>;
		};

		shmem24: scmi-sram@d0018000 {
			compatible = "arm,scmi-shmem";
			reg = <0xd0018000 0x1000>;
		};

		shmem25: scmi-sram@d0019000 {
			compatible = "arm,scmi-shmem";
			reg = <0xd0019000 0x1000>;
		};

		shmem26: scmi-sram@d001a000 {
			compatible = "arm,scmi-shmem";
			reg = <0xd001a000 0x1000>;
		};

		shmem27: scmi-sram@d001b000 {
			compatible = "arm,scmi-shmem";
			reg = <0xd001b000 0x1000>;
		};

		shmem28: scmi-sram@d001c000 {
			compatible = "arm,scmi-shmem";
			reg = <0xd001c000 0x1000>;
		};

		shmem29: scmi-sram@d001d000 {
			compatible = "arm,scmi-shmem";
			reg = <0xd001d000 0x1000>;
		};

		shmem30: scmi-sram@d001e000 {
			compatible = "arm,scmi-shmem";
			reg = <0xd001e000 0x1000>;
		};

		shmem31: scmi-sram@d001f000 {
			compatible = "arm,scmi-shmem";
			reg = <0xd001f000 0x1000>;
		};

		shmem32: scmi-sram@d0020000 {
			compatible = "arm,scmi-shmem";
			reg = <0xd0020000 0x1000>;
		};

		shmem33: scmi-sram@d0021000 {
			compatible = "arm,scmi-shmem";
			reg = <0xd0021000 0x1000>;
		};

		shmem34: scmi-sram@d0022000 {
			compatible = "arm,scmi-shmem";
			reg = <0xd0022000 0x1000>;
		};

		shmem35: scmi-sram@d0023000 {
			compatible = "arm,scmi-shmem";
			reg = <0xd0023000 0x1000>;
		};

		shmem36: scmi-sram@d0024000 {
			compatible = "arm,scmi-shmem";
			reg = <0xd0024000 0x1000>;
		};

		shmem37: scmi-sram@d0025000 {
			compatible = "arm,scmi-shmem";
			reg = <0xd0025000 0x1000>;
		};

		shmem38: scmi-sram@d0026000 {
			compatible = "arm,scmi-shmem";
			reg = <0xd0026000 0x1000>;
		};

		shmem39: scmi-sram@d0027000 {
			compatible = "arm,scmi-shmem";
			reg = <0xd0027000 0x1000>;
		};

		shmem40: scmi-sram@d0028000 {
			compatible = "arm,scmi-shmem";
			reg = <0xd0028000 0x1000>;
		};

		shmem41: scmi-sram@d0029000 {
			compatible = "arm,scmi-shmem";
			reg = <0xd0029000 0x1000>;
		};

		shmem42: scmi-sram@d002a000 {
			compatible = "arm,scmi-shmem";
			reg = <0xd002a000 0x1000>;
		};

		shmem43: scmi-sram@d002b000 {
			compatible = "arm,scmi-shmem";
			reg = <0xd002b000 0x1000>;
		};

		shmem44: scmi-sram@d002c000 {
			compatible = "arm,scmi-shmem";
			reg = <0xd002c000 0x1000>;
		};

		shmem45: scmi-sram@d002d000 {
			compatible = "arm,scmi-shmem";
			reg = <0xd002d000 0x1000>;
		};

		shmem46: scmi-sram@d002e000 {
			compatible = "arm,scmi-shmem";
			reg = <0xd002e000 0x1000>;
		};

		shmem47: scmi-sram@d002f000 {
			compatible = "arm,scmi-shmem";
			reg = <0xd002f000 0x1000>;
		};

		shmem48: scmi-sram@d0030000 {
			compatible = "arm,scmi-shmem";
			reg = <0xd0030000 0x1000>;
		};

		shmem49: scmi-sram@d0031000 {
			compatible = "arm,scmi-shmem";
			reg = <0xd0031000 0x1000>;
		};

		shmem50: scmi-sram@d0032000 {
			compatible = "arm,scmi-shmem";
			reg = <0xd0032000 0x1000>;
		};

		shmem51: scmi-sram@d0033000 {
			compatible = "arm,scmi-shmem";
			reg = <0xd0033000 0x1000>;
		};

		shmem52: scmi-sram@d0034000 {
			compatible = "arm,scmi-shmem";
			reg = <0xd0034000 0x1000>;
		};

		shmem53: scmi-sram@d0035000 {
			compatible = "arm,scmi-shmem";
			reg = <0xd0035000 0x1000>;
		};

		shmem54: scmi-sram@d0036000 {
			compatible = "arm,scmi-shmem";
			reg = <0xd0036000 0x1000>;
		};

		shmem55: scmi-sram@d0037000 {
			compatible = "arm,scmi-shmem";
			reg = <0xd0037000 0x1000>;
		};

		shmem56: scmi-sram@d0038000 {
			compatible = "arm,scmi-shmem";
			reg = <0xd0038000 0x1000>;
		};

		shmem57: scmi-sram@d0039000 {
			compatible = "arm,scmi-shmem";
			reg = <0xd0039000 0x1000>;
		};

		shmem58: scmi-sram@d003a000 {
			compatible = "arm,scmi-shmem";
			reg = <0xd003a000 0x1000>;
		};

		shmem59: scmi-sram@d003b000 {
			compatible = "arm,scmi-shmem";
			reg = <0xd003b000 0x1000>;
		};

		shmem60: scmi-sram@d003c000 {
			compatible = "arm,scmi-shmem";
			reg = <0xd003c000 0x1000>;
		};

		shmem61: scmi-sram@d003d000 {
			compatible = "arm,scmi-shmem";
			reg = <0xd003d000 0x1000>;
		};

		shmem62: scmi-sram@d003e000 {
			compatible = "arm,scmi-shmem";
			reg = <0xd003e000 0x1000>;
		};

		shmem63: scmi-sram@d003f000 {
			compatible = "arm,scmi-shmem";
			reg = <0xd003f000 0x1000>;
		};
	};
};
